# ARM_Cortex_M register map
File version: 1.0
ARM 32-bit Cortex-M Microcontroller
Registers are 32-bit, read-write, reset 0x0 unless marked. A register's access mark holds for its fields unless they carry their own. Offsets are from the block's base; lines under a group give offsets from that group; [hi:lo] are bit positions; {n}, {i} and the like mark numbered series; 'fields as' and 'values as' point back to an identical list; <NAME> marks a mode.

## Memory map
0xE000ED00 Debug size 0x100

## Debug
Base 0xE000ED00
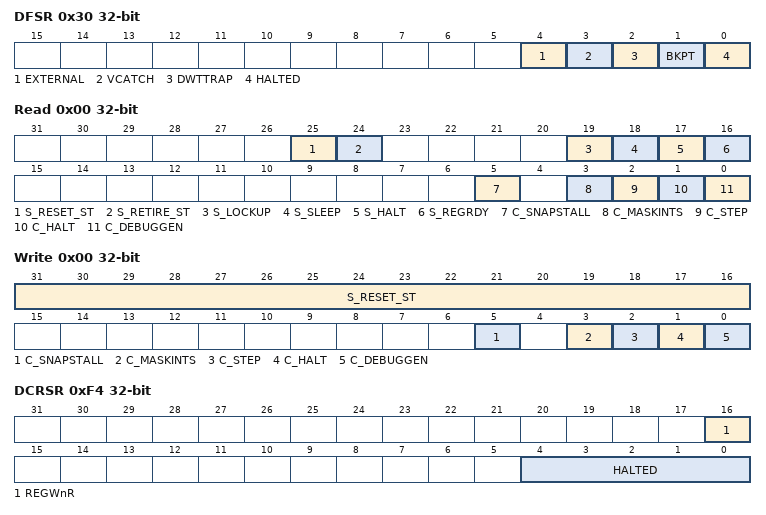
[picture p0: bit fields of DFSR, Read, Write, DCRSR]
0x30 DFSR — Debug Fault Status Register
  [4] EXTERNAL — An asynchronous exception generated due to the assertion of EDBGRQ.
  [3] VCATCH — Vector catch triggered. Corresponding FSR will contain the primary cause of the exception.
  [2] DWTTRAP — Data Watchpoint and Trace trap. Indicates that the core halted due to at least one DWT trap event.
  [1] BKPT — BKPT instruction executed or breakpoint match in FPB.
  [0] HALTED
0xF0 DHCSR group — Debug Halting Control and Status Register
  0x00 Read ro
    [25] S_RESET_ST, [24] S_RETIRE_ST, [19] S_LOCKUP, [18] S_SLEEP, [17] S_HALT, [16] S_REGRDY, [5] C_SNAPSTALL, [3] C_MASKINTS, [2] C_STEP, [1] C_HALT, [0] C_DEBUGGEN
  0x00 Write wo
    [31:16] S_RESET_ST — Debug Key. The value 0xA05F must be written to enable write accesses to bits [15:0], otherwise the write access will be ignored. Read behavior of bits [31:16] is as listed below.
    [5] C_SNAPSTALL
    [3] C_MASKINTS
    [2] C_STEP
    [1] C_HALT
    [0] C_DEBUGGEN
0xF4 DCRSR wo — Debug Core Register Selector Register: The DCRSR write-only register generates a handshake to the core to transfer the selected register to/from the DCRDR. The DHCSR S_REGRDY bit is cleared when the DCRSR is written, and remains clear until the core transaction completes. This register is only accessible from Debug state.
  [16] REGWnR
    1=Write; 0=Read
  [4:0] HALTED
    {v}=Register_{v} (v=0..12); 13=Current_SP; 14=Link_Rregister; 15=Debug_Return_Address; 16=xPSR; 17=MSP; 18=PSP; 19=CONTROL_FAULTMASK_BASEPRI_PRIMASK
0xF8 DCRDR — Debug Core Register Data Register
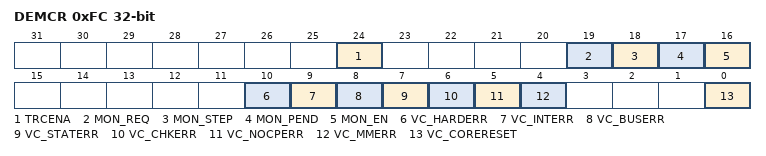
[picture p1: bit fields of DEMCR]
0xFC DEMCR — Debug Exception and Monitor Control Register
  [24] TRCENA, [19] MON_REQ, [18] MON_STEP, [17] MON_PEND, [16] MON_EN, [10] VC_HARDERR, [9] VC_INTERR, [8] VC_BUSERR, [7] VC_STATERR, [6] VC_CHKERR, [5] VC_NOCPERR, [4] VC_MMERR, [0] VC_CORERESET

## Notices in the file
Copyright (C) 2016 AdaCore
